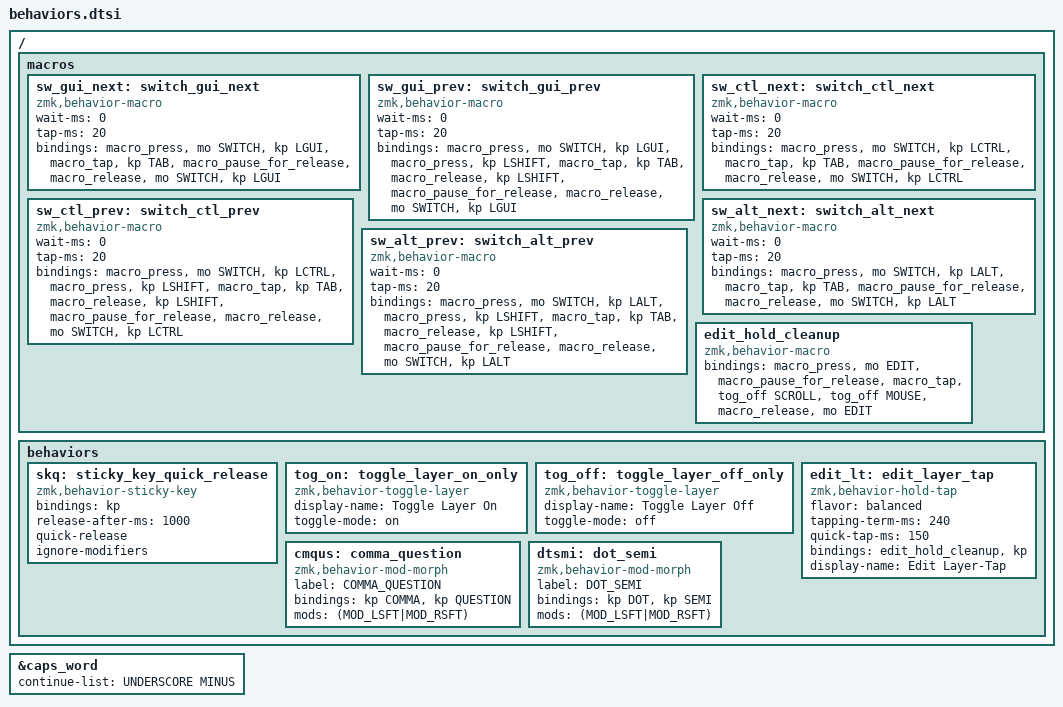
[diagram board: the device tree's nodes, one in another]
/ {
    macros {
        sw_gui_next: switch_gui_next {
            compatible = "zmk,behavior-macro";
            #binding-cells = <0>;
            wait-ms = <0>;
            tap-ms = <20>;
            bindings
                = <&macro_press &mo SWITCH &kp LGUI>
                , <&macro_tap &kp TAB>
                , <&macro_pause_for_release>
                , <&macro_release &mo SWITCH &kp LGUI>
                ;
        };

        sw_gui_prev: switch_gui_prev {
            compatible = "zmk,behavior-macro";
            #binding-cells = <0>;
            wait-ms = <0>;
            tap-ms = <20>;
            bindings
                = <&macro_press &mo SWITCH &kp LGUI>
                , <&macro_press &kp LSHIFT>
                , <&macro_tap &kp TAB>
                , <&macro_release &kp LSHIFT>
                , <&macro_pause_for_release>
                , <&macro_release &mo SWITCH &kp LGUI>
                ;
        };

        sw_ctl_next: switch_ctl_next {
            compatible = "zmk,behavior-macro";
            #binding-cells = <0>;
            wait-ms = <0>;
            tap-ms = <20>;
            bindings
                = <&macro_press &mo SWITCH &kp LCTRL>
                , <&macro_tap &kp TAB>
                , <&macro_pause_for_release>
                , <&macro_release &mo SWITCH &kp LCTRL>
                ;
        };

        sw_ctl_prev: switch_ctl_prev {
            compatible = "zmk,behavior-macro";
            #binding-cells = <0>;
            wait-ms = <0>;
            tap-ms = <20>;
            bindings
                = <&macro_press &mo SWITCH &kp LCTRL>
                , <&macro_press &kp LSHIFT>
                , <&macro_tap &kp TAB>
                , <&macro_release &kp LSHIFT>
                , <&macro_pause_for_release>
                , <&macro_release &mo SWITCH &kp LCTRL>
                ;
        };

        sw_alt_next: switch_alt_next {
            compatible = "zmk,behavior-macro";
            #binding-cells = <0>;
            wait-ms = <0>;
            tap-ms = <20>;
            bindings
                = <&macro_press &mo SWITCH &kp LALT>
                , <&macro_tap &kp TAB>
                , <&macro_pause_for_release>
                , <&macro_release &mo SWITCH &kp LALT>
                ;
        };

        sw_alt_prev: switch_alt_prev {
            compatible = "zmk,behavior-macro";
            #binding-cells = <0>;
            wait-ms = <0>;
            tap-ms = <20>;
            bindings
                = <&macro_press &mo SWITCH &kp LALT>
                , <&macro_press &kp LSHIFT>
                , <&macro_tap &kp TAB>
                , <&macro_release &kp LSHIFT>
                , <&macro_pause_for_release>
                , <&macro_release &mo SWITCH &kp LALT>
                ;
        };

        edit_hold_cleanup: edit_hold_cleanup {
            compatible = "zmk,behavior-macro";
            #binding-cells = <0>;
            bindings
                = <&macro_press &mo EDIT>
                , <&macro_pause_for_release>
                , <&macro_tap &tog_off SCROLL &tog_off MOUSE>
                , <&macro_release &mo EDIT>
                ;
        };
    };

    behaviors {
        skq: sticky_key_quick_release {
            compatible = "zmk,behavior-sticky-key";
            #binding-cells = <1>;
            bindings = <&kp>;
            release-after-ms = <1000>;
            quick-release;
            ignore-modifiers;
        };

        tog_on: toggle_layer_on_only {
            compatible = "zmk,behavior-toggle-layer";
            #binding-cells = <1>;
            display-name = "Toggle Layer On";
            toggle-mode = "on";
        };

        tog_off: toggle_layer_off_only {
            compatible = "zmk,behavior-toggle-layer";
            #binding-cells = <1>;
            display-name = "Toggle Layer Off";
            toggle-mode = "off";
        };

        edit_lt: edit_layer_tap {
            compatible = "zmk,behavior-hold-tap";
            #binding-cells = <2>;
            flavor = "balanced";
            tapping-term-ms = <240>;
            quick-tap-ms = <150>;
            bindings = <&edit_hold_cleanup>, <&kp>;
            display-name = "Edit Layer-Tap";
        };      

        // Mod-morphs
        cmqus: comma_question {
            compatible = "zmk,behavior-mod-morph";
            label = "COMMA_QUESTION";
            #binding-cells = <0>;
            bindings = <&kp COMMA>, <&kp QUESTION>;
            mods = <(MOD_LSFT|MOD_RSFT)>;
        };

        dtsmi: dot_semi {
            compatible = "zmk,behavior-mod-morph";
            label = "DOT_SEMI";
            #binding-cells = <0>;
            bindings = <&kp DOT>, <&kp SEMI>;
            mods = <(MOD_LSFT|MOD_RSFT)>;
        };
    };
};

// Caps word configuration
&caps_word {
    continue-list = <UNDERSCORE MINUS>;
};
